AUTOSAR XML (schema 314)
package /ComponentType
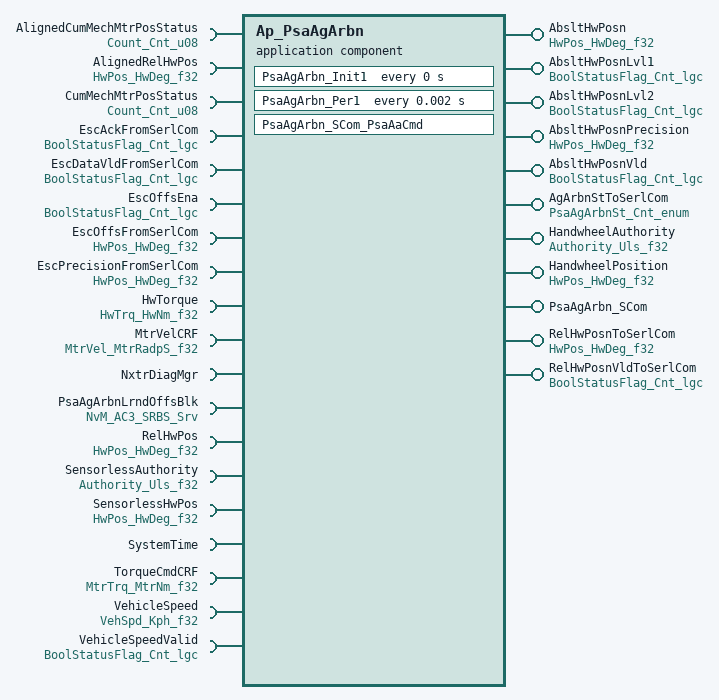
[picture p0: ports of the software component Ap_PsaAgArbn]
  application software component type Ap_PsaAgArbn
    11 x provide port:
      AbsltHwPosn: unqueued-sender-com-spec{data-element=HwDeg_f32, can-invalidate=false, init-value=D_ZERO_ULS_F32}, provided-interface=HwPos_HwDeg_f32
      AbsltHwPosnLvl1: unqueued-sender-com-spec{data-element=Cnt_lgc, can-invalidate=false, init-value=D_FALSE_CNT_LGC}, provided-interface=BoolStatusFlag_Cnt_lgc
      AbsltHwPosnLvl2: unqueued-sender-com-spec{data-element=Cnt_lgc, can-invalidate=false, init-value=D_FALSE_CNT_LGC}, provided-interface=BoolStatusFlag_Cnt_lgc
      AbsltHwPosnPrecision: unqueued-sender-com-spec{data-element=HwDeg_f32, can-invalidate=false, init-value=D_ZERO_ULS_F32}, provided-interface=HwPos_HwDeg_f32
      AbsltHwPosnVld: unqueued-sender-com-spec{data-element=Cnt_lgc, can-invalidate=false, init-value=D_FALSE_CNT_LGC}, provided-interface=BoolStatusFlag_Cnt_lgc
      AgArbnStToSerlCom: unqueued-sender-com-spec{data-element=Cnt_enum, can-invalidate=false, init-value=D_PSAAGARBNSTINIT_CNT_ENUM}, provided-interface=PsaAgArbnSt_Cnt_enum
      HandwheelAuthority: unqueued-sender-com-spec{data-element=Uls_f32, can-invalidate=false, init-value=D_ZERO_ULS_F32}, provided-interface=Authority_Uls_f32
      HandwheelPosition: unqueued-sender-com-spec{data-element=HwDeg_f32, can-invalidate=false, init-value=D_ZERO_ULS_F32}, provided-interface=HwPos_HwDeg_f32
      PsaAgArbn_SCom: server-com-spec{operation=PsaAaCmd, queue-length=1}, provided-interface=PsaAgArbn_SCom
      RelHwPosnToSerlCom: unqueued-sender-com-spec{data-element=HwDeg_f32, can-invalidate=false, init-value=D_ZERO_ULS_F32}, provided-interface=HwPos_HwDeg_f32
      RelHwPosnVldToSerlCom: unqueued-sender-com-spec{data-element=Cnt_lgc, can-invalidate=false, init-value=D_FALSE_CNT_LGC}, provided-interface=BoolStatusFlag_Cnt_lgc
    19 x require port:
      AlignedCumMechMtrPosStatus: unqueued-receiver-com-spec{data-element=Cnt_u08, init-value=D_ZERO_CNT_U8}, required-interface=Count_Cnt_u08
      AlignedRelHwPos: unqueued-receiver-com-spec{data-element=HwDeg_f32, init-value=D_ZERO_ULS_F32}, required-interface=HwPos_HwDeg_f32
      CumMechMtrPosStatus: unqueued-receiver-com-spec{data-element=Cnt_u08, init-value=D_ZERO_CNT_U8}, required-interface=Count_Cnt_u08
      EscAckFromSerlCom: unqueued-receiver-com-spec{data-element=Cnt_lgc, init-value=D_FALSE_CNT_LGC}, required-interface=BoolStatusFlag_Cnt_lgc
      EscDataVldFromSerlCom: unqueued-receiver-com-spec{data-element=Cnt_lgc, init-value=D_FALSE_CNT_LGC}, required-interface=BoolStatusFlag_Cnt_lgc
      EscOffsEna: unqueued-receiver-com-spec{data-element=Cnt_lgc, init-value=D_FALSE_CNT_LGC}, required-interface=BoolStatusFlag_Cnt_lgc
      EscOffsFromSerlCom: unqueued-receiver-com-spec{data-element=HwDeg_f32, init-value=D_ZERO_ULS_F32}, required-interface=HwPos_HwDeg_f32
      EscPrecisionFromSerlCom: unqueued-receiver-com-spec{data-element=HwDeg_f32, init-value=D_ZERO_ULS_F32}, required-interface=HwPos_HwDeg_f32
      HwTorque: unqueued-receiver-com-spec{data-element=HwNm_f32, init-value=D_ZERO_ULS_F32}, required-interface=HwTrq_HwNm_f32
      MtrVelCRF: unqueued-receiver-com-spec{data-element=MtrRadpS_f32, init-value=D_ZERO_ULS_F32}, required-interface=MtrVel_MtrRadpS_f32
      NxtrDiagMgr: required-com-specs=[GetNTCActive, GetNTCFailed, GetNTCStatus, SetNTCStatus], required-interface=NxtrDiagMgr
      PsaAgArbnLrndOffsBlk: required-com-specs=[EraseBlock, GetErrorStatus, InvalidateNvBlock, ReadBlock, SetRamBlockStatus, WriteBlock], required-interface=NvM_AC3_SRBS_Srv
      RelHwPos: unqueued-receiver-com-spec{data-element=HwDeg_f32, init-value=D_ZERO_ULS_F32}, required-interface=HwPos_HwDeg_f32
      SensorlessAuthority: unqueued-receiver-com-spec{data-element=Uls_f32, init-value=D_ZERO_ULS_F32}, required-interface=Authority_Uls_f32
      SensorlessHwPos: unqueued-receiver-com-spec{data-element=HwDeg_f32, init-value=D_ZERO_ULS_F32}, required-interface=HwPos_HwDeg_f32
      SystemTime: required-interface=SystemTime
        required-com-specs:
          DtrmnElapsedTime_mS_u16
          DtrmnElapsedTime_mS_u32
          DtrmnElapsedTime_uS_u16
          DtrmnElapsedTime_uS_u32
          GetSystemTime_mS_u32
          GetSystemTime_uS_u32
      TorqueCmdCRF: unqueued-receiver-com-spec{data-element=MtrNm_f32, init-value=D_ZERO_ULS_F32}, required-interface=MtrTrq_MtrNm_f32
      VehicleSpeed: unqueued-receiver-com-spec{data-element=Kph_f32, init-value=D_ZERO_ULS_F32}, required-interface=VehSpd_Kph_f32
      VehicleSpeedValid: unqueued-receiver-com-spec{data-element=Cnt_lgc, init-value=D_FALSE_CNT_LGC}, required-interface=BoolStatusFlag_Cnt_lgc
  internal behavior Ap_PsaAgArbn_InternalBehavior: component=Ap_PsaAgArbn
    timing event PsaAgArbn_Init1_InitEvent: start-on-event=PsaAgArbn_Init1, period=0
    timing event TMT_PsaAgArbn_Per1: start-on-event=PsaAgArbn_Per1, period=0.002
    operation invoked event OIT_PsaAgArbn_SCom_PsaAaCmd_PsaAgArbn_SCom_PsaAaCmd: start-on-event=PsaAgArbn_SCom_PsaAaCmd, operation=PsaAgArbn_SCom.PsaAaCmd
    per instance memory PsaAgArbnLrndOffsData: type=PsaAgAnLrndOffs_Str, type-definition=/DataType/PsaAgAnLrndOffs_Str
    port-api-options:
      enable-take-address=false, indirect-api=false, port=AbsltHwPosn
      enable-take-address=false, indirect-api=false, port=AbsltHwPosnLvl1
      enable-take-address=false, indirect-api=false, port=AbsltHwPosnLvl2
      enable-take-address=false, indirect-api=false, port=AbsltHwPosnPrecision
      enable-take-address=false, indirect-api=false, port=AbsltHwPosnVld
      enable-take-address=false, indirect-api=false, port=AgArbnStToSerlCom
      enable-take-address=false, indirect-api=false, port=AlignedCumMechMtrPosStatus
      enable-take-address=false, indirect-api=false, port=AlignedRelHwPos
      enable-take-address=false, indirect-api=false, port=CumMechMtrPosStatus
      enable-take-address=false, indirect-api=false, port=EscAckFromSerlCom
      enable-take-address=false, indirect-api=false, port=EscDataVldFromSerlCom
      enable-take-address=false, indirect-api=false, port=EscOffsEna
      enable-take-address=false, indirect-api=false, port=EscOffsFromSerlCom
      enable-take-address=false, indirect-api=false, port=EscPrecisionFromSerlCom
      enable-take-address=false, indirect-api=false, port=HandwheelAuthority
      enable-take-address=false, indirect-api=false, port=HandwheelPosition
      enable-take-address=false, indirect-api=false, port=HwTorque
      enable-take-address=false, indirect-api=false, port=MtrVelCRF
      enable-take-address=false, indirect-api=false, port=NxtrDiagMgr
      enable-take-address=false, indirect-api=false, port=PsaAgArbn_SCom
      enable-take-address=false, indirect-api=false, port=PsaAgArbnLrndOffsBlk
      enable-take-address=false, indirect-api=false, port=RelHwPos
      enable-take-address=false, indirect-api=false, port=RelHwPosnToSerlCom
      enable-take-address=false, indirect-api=false, port=RelHwPosnVldToSerlCom
      enable-take-address=false, indirect-api=false, port=SensorlessAuthority
      enable-take-address=false, indirect-api=false, port=SensorlessHwPos
      enable-take-address=false, indirect-api=false, port=SystemTime
      enable-take-address=false, indirect-api=false, port=TorqueCmdCRF
      enable-take-address=false, indirect-api=false, port=VehicleSpeed
      enable-take-address=false, indirect-api=false, port=VehicleSpeedValid
    runnable PsaAgArbn_Init1  # Function initialization. It sets the NTC to PASSED, checks NVM validity and writes default values for Used Offset and Computed Offset.
      data read access READ_EscOffsEna_Cnt_lgc: data-element=EscOffsEna.Cnt_lgc
      4 x sync call, all with timeout=0:
        SC_NxtrDiagMgr_GetNTCActive: operation=NxtrDiagMgr.GetNTCActive
        SC_NxtrDiagMgr_SetNTCStatus: operation=NxtrDiagMgr.SetNTCStatus
        SC_PsaAgArbnLrndOffsBlk_GetErrorStatus: operation=PsaAgArbnLrndOffsBlk.GetErrorStatus
        SC_PsaAgArbnLrndOffsBlk_SetRamBlockStatus: operation=PsaAgArbnLrndOffsBlk.SetRamBlockStatus
    runnable PsaAgArbn_Per1  # Periodic Runnable executed at every 0.002 sec zone 10b.
      16 x data read access:
        READ_AlignedCumMechMtrPosStatus_Cnt_u08: data-element=AlignedCumMechMtrPosStatus.Cnt_u08
        READ_AlignedRelHwPos_HwDeg_f32: data-element=AlignedRelHwPos.HwDeg_f32
        READ_CumMechMtrPosStatus_Cnt_u08: data-element=CumMechMtrPosStatus.Cnt_u08
        READ_EscAckFromSerlCom_Cnt_lgc: data-element=EscAckFromSerlCom.Cnt_lgc
        READ_EscDataVldFromSerlCom_Cnt_lgc: data-element=EscDataVldFromSerlCom.Cnt_lgc
        READ_EscOffsEna_Cnt_lgc: data-element=EscOffsEna.Cnt_lgc
        READ_EscOffsFromSerlCom_HwDeg_f32: data-element=EscOffsFromSerlCom.HwDeg_f32
        READ_EscPrecisionFromSerlCom_HwDeg_f32: data-element=EscPrecisionFromSerlCom.HwDeg_f32
        READ_HwTorque_HwNm_f32: data-element=HwTorque.HwNm_f32
        READ_MtrVelCRF_MtrRadpS_f32: data-element=MtrVelCRF.MtrRadpS_f32
        READ_RelHwPos_HwDeg_f32: data-element=RelHwPos.HwDeg_f32
        READ_SensorlessAuthority_Uls_f32: data-element=SensorlessAuthority.Uls_f32
        READ_SensorlessHwPos_HwDeg_f32: data-element=SensorlessHwPos.HwDeg_f32
        READ_TorqueCmdCRF_MtrNm_f32: data-element=TorqueCmdCRF.MtrNm_f32
        READ_VehicleSpeed_Kph_f32: data-element=VehicleSpeed.Kph_f32
        READ_VehicleSpeedValid_Cnt_lgc: data-element=VehicleSpeedValid.Cnt_lgc
      10 x data write access:
        WRITE_AbsltHwPosn_HwDeg_f32: data-element=AbsltHwPosn.HwDeg_f32
        WRITE_AbsltHwPosnLvl1_Cnt_lgc: data-element=AbsltHwPosnLvl1.Cnt_lgc
        WRITE_AbsltHwPosnLvl2_Cnt_lgc: data-element=AbsltHwPosnLvl2.Cnt_lgc
        WRITE_AbsltHwPosnPrecision_HwDeg_f32: data-element=AbsltHwPosnPrecision.HwDeg_f32
        WRITE_AbsltHwPosnVld_Cnt_lgc: data-element=AbsltHwPosnVld.Cnt_lgc
        WRITE_AgArbnStToSerlCom_Cnt_enum: data-element=AgArbnStToSerlCom.Cnt_enum
        WRITE_HandwheelAuthority_Uls_f32: data-element=HandwheelAuthority.Uls_f32
        WRITE_HandwheelPosition_HwDeg_f32: data-element=HandwheelPosition.HwDeg_f32
        WRITE_RelHwPosnToSerlCom_HwDeg_f32: data-element=RelHwPosnToSerlCom.HwDeg_f32
        WRITE_RelHwPosnVldToSerlCom_Cnt_lgc: data-element=RelHwPosnVldToSerlCom.Cnt_lgc
      4 x sync call, all with timeout=0:
        SC_NxtrDiagMgr_SetNTCStatus: operation=NxtrDiagMgr.SetNTCStatus
        SC_PsaAgArbnLrndOffsBlk_SetRamBlockStatus: operation=PsaAgArbnLrndOffsBlk.SetRamBlockStatus
        SC_SystemTime_DtrmnElapsedTime_uS_u32: operation=SystemTime.DtrmnElapsedTime_uS_u32
        SC_SystemTime_GetSystemTime_mS_u32: operation=SystemTime.GetSystemTime_mS_u32
    runnable PsaAgArbn_SCom_PsaAaCmd  # Diagnostic Service to write values for UsedOffset and NVM RAM block.
      sync call SC_PsaAgArbnLrndOffsBlk_WriteBlock: operation=PsaAgArbnLrndOffsBlk.WriteBlock, timeout=0
    service-needss:
      swc nv block needs PsaAgArbnLrndOffsBlk: n-data-sets=0, readonly=false, reliability=LOW, resistant-to-changed-sw=false, restore-at-start=false, write-only-once=false, writing-frequency=0, writing-priority=LOW, mirror-block=PsaAgArbnLrndOffsData
  swc implementation Ap_PsaAgArbn_Implementation: behavior=Ap_PsaAgArbn_InternalBehavior
    code-descriptors:
      code Code: type=SRC
